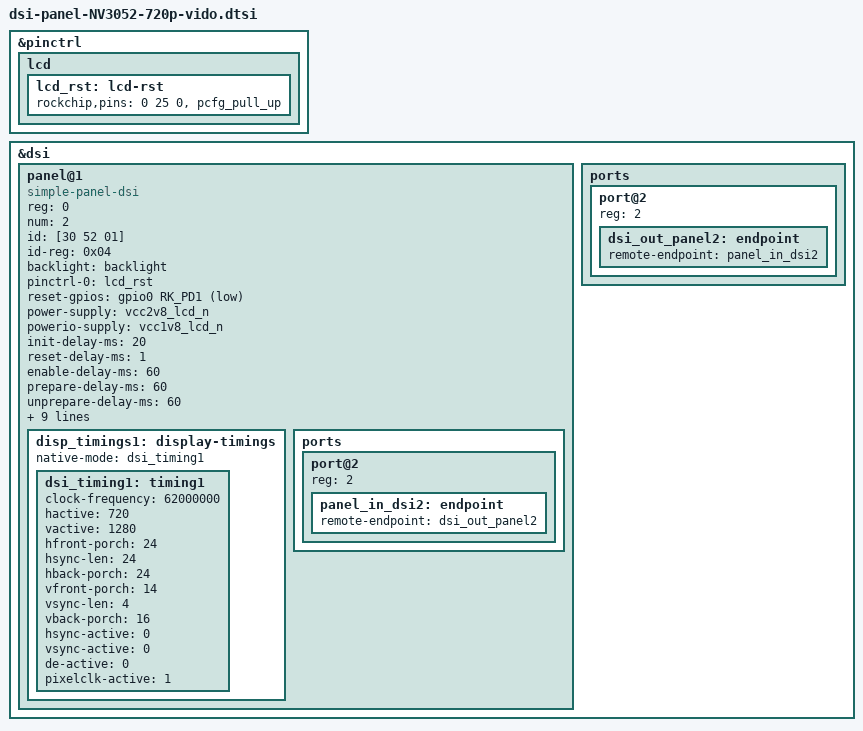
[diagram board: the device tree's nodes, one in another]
&pinctrl {
	lcd {
		lcd_rst: lcd-rst {
				rockchip,pins =
					<0 25 0 &pcfg_pull_up>;
		};
	};
};

&dsi {
	panel@1 {
		status = "okay";
		compatible = "simple-panel-dsi";
		reg = <0>;
		num = <2>;
		id = [30 52 01];
		id-reg = <0x04>;
		backlight = <&backlight>;
        pinctrl-names = "default";
        pinctrl-0 = <&lcd_rst>;
        reset-gpios = <&gpio0 RK_PD1 GPIO_ACTIVE_LOW>;
		power-supply = <&vcc2v8_lcd_n>;
	    powerio-supply = <&vcc1v8_lcd_n>;
        init-delay-ms = <20>;
		reset-delay-ms = <1>;
		enable-delay-ms = <60>;
		prepare-delay-ms = <60>;
		unprepare-delay-ms = <60>;
		disable-delay-ms = <60>;
		dsi,flags = <(MIPI_DSI_MODE_VIDEO | MIPI_DSI_MODE_VIDEO_BURST |	MIPI_DSI_MODE_LPM)>;
		dsi,format = <MIPI_DSI_FMT_RGB888>;
		dsi,lanes  = <4>;
		panel-init-sequence = [
			13 78 01 11
			13 14 01 29
		];

		panel-exit-sequence = [
			13 32 01 28
			13 78 01 10
		];

		disp_timings1:display-timings {
			native-mode = <&dsi_timing1>;
			dsi_timing1: timing1 {
				clock-frequency = <62000000>;
				hactive = <720>;
				vactive = <1280>;
				hfront-porch = <24>;
				hsync-len = <24>;
				hback-porch = <24>;
				vfront-porch = <14>;
				vsync-len = <4>;
				vback-porch = <16>;
				hsync-active = <0>;
				vsync-active = <0>;
				de-active = <0>;
				pixelclk-active = <1>;
			};
		};
		ports {
			#address-cells = <1>;
			#size-cells = <0>;

			port@2 {
				reg = <2>;
				panel_in_dsi2: endpoint {
					remote-endpoint = <&dsi_out_panel2>;
				};
			};
		};
	};

	ports {
		#address-cells = <1>;
		#size-cells = <0>;

		port@2 {
			reg = <2>;
			dsi_out_panel2: endpoint {
				remote-endpoint = <&panel_in_dsi2>;
			};
		};
	};

};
